AUTOSAR XML (schema 4-2-2)
package /STELLANTIS/EPT/ASWCs
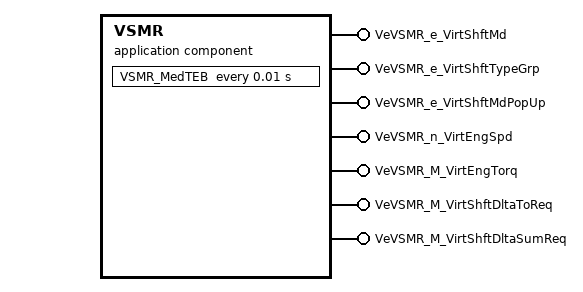
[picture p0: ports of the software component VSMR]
  application sw component type VSMR
    7 x provide port:
      VeVSMR_e_VirtShftMd: nonqueued-sender-com-spec{data-element=Value, init-value=CeVSMR_e_VS_Enabled}, provided-interface=VeVSMR_e_VirtShftMd
      VeVSMR_e_VirtShftTypeGrp: nonqueued-sender-com-spec{data-element=Value, init-value=CeVSMR_e_VST_NoShift}, provided-interface=VeVSMR_e_VirtShftTypeGrp
      VeVSMR_e_VirtShftMdPopUp: nonqueued-sender-com-spec{data-element=Value, init-value=CeVSMR_e_MSG_NoIssue}, provided-interface=VeVSMR_e_VirtShftMdPopUp
      VeVSMR_n_VirtEngSpd: nonqueued-sender-com-spec{data-element=Value, init-value=0}, provided-interface=VeVSMR_n_VirtEngSpd
      VeVSMR_M_VirtEngTorq: nonqueued-sender-com-spec{data-element=Value, init-value=0}, provided-interface=VeVSMR_M_VirtEngTorq
      VeVSMR_M_VirtShftDltaToReq: nonqueued-sender-com-spec{data-element=Value, init-value=0}, provided-interface=VeVSMR_M_VirtShftDltaToReq
      VeVSMR_M_VirtShftDltaSumReq: nonqueued-sender-com-spec{data-element=Value, init-value=0}, provided-interface=VeVSMR_M_VirtShftDltaSumReq
    behavior IB_VSMR: data-type-mapping=msADTtoIDTMapping, handle-termination-and-restart=NO-SUPPORT
      timing event Event_MedTEB: start-on-event=VSMR_MedTEB, period=0.01
      4 x init event:
        Event_VSMR_ac_Init: start-on-event=VSMR_ac_Init
        Event_PwrOn: start-on-event=VSMR_PwrOn
        Event_PwrOff: start-on-event=VSMR_PwrOff
        Event_PUP: start-on-event=VSMR_PUP
      5 x runnable:
        VSMR_ac_Init
          data-send-points:
            access OUT_VeVSMR_e_VirtShftMd_Value: accessed-variable=VeVSMR_e_VirtShftMd.Value
            access OUT_VeVSMR_e_VirtShftTypeGrp_Value: accessed-variable=VeVSMR_e_VirtShftTypeGrp.Value
            access OUT_VeVSMR_e_VirtShftMdPopUp_Value: accessed-variable=VeVSMR_e_VirtShftMdPopUp.Value
        VSMR_PwrOn
          data-send-points:
            7 x access:
              OUT_VeVSMR_e_VirtShftMd_Value: accessed-variable=VeVSMR_e_VirtShftMd.Value
              OUT_VeVSMR_e_VirtShftTypeGrp_Value: accessed-variable=VeVSMR_e_VirtShftTypeGrp.Value
              OUT_VeVSMR_e_VirtShftMdPopUp_Value: accessed-variable=VeVSMR_e_VirtShftMdPopUp.Value
              OUT_VeVSMR_n_VirtEngSpd_Value: accessed-variable=VeVSMR_n_VirtEngSpd.Value
              OUT_VeVSMR_M_VirtEngTorq_Value: accessed-variable=VeVSMR_M_VirtEngTorq.Value
              OUT_VeVSMR_M_VirtShftDltaToReq_Value: accessed-variable=VeVSMR_M_VirtShftDltaToReq.Value
              OUT_VeVSMR_M_VirtShftDltaSumReq_Value: accessed-variable=VeVSMR_M_VirtShftDltaSumReq.Value
        VSMR_MedTEB
          data-send-points:
            7 x access:
              OUT_VeVSMR_e_VirtShftMd_Value: accessed-variable=VeVSMR_e_VirtShftMd.Value
              OUT_VeVSMR_e_VirtShftTypeGrp_Value: accessed-variable=VeVSMR_e_VirtShftTypeGrp.Value
              OUT_VeVSMR_e_VirtShftMdPopUp_Value: accessed-variable=VeVSMR_e_VirtShftMdPopUp.Value
              OUT_VeVSMR_n_VirtEngSpd_Value: accessed-variable=VeVSMR_n_VirtEngSpd.Value
              OUT_VeVSMR_M_VirtEngTorq_Value: accessed-variable=VeVSMR_M_VirtEngTorq.Value
              OUT_VeVSMR_M_VirtShftDltaToReq_Value: accessed-variable=VeVSMR_M_VirtShftDltaToReq.Value
              OUT_VeVSMR_M_VirtShftDltaSumReq_Value: accessed-variable=VeVSMR_M_VirtShftDltaSumReq.Value
        VSMR_PwrOff
        VSMR_PUP
      variation point proxy Variant_VSMR_eRuptEnabled: category=CONDITION, condition-access=0
